# PIC32CX5112MTSH128S1 register map
Vendor: Microchip Technology; Series: PIC32CXMTSH; File version: 0
CPU: CM4 r0p1, selectable endian, MPU, FPU, 4 interrupt priority bits
Registers are 32-bit, read-write, reset 0x0 unless marked. A register's access mark holds for its fields unless they carry their own. Offsets are from the block's base; [hi:lo] are bit positions; lines under a group give offsets from that group; {n}, {i} and the like mark numbered series; 'fields as' and 'values as' point back to an identical list.

## TC0 — Timer Counter
Base 0x40038000; register names take the prefix TC_
Same registers: TC1 0x4003C000, TC2 0x40040000, TC3 0x48008000
{0x0+0x40*i} TC_CHANNEL[{i}] (i=0..2) group
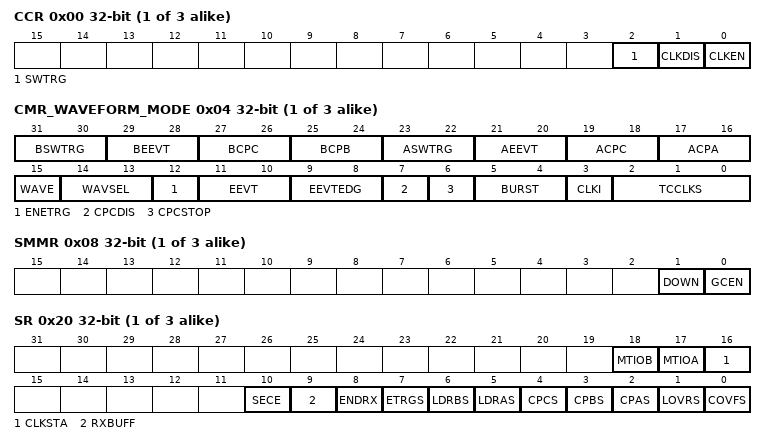
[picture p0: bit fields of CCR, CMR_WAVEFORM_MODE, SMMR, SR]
  0x00 CCR wo — Channel Control Register
    [2] SWTRG — Software Trigger Command
    [1] CLKDIS — Counter Clock Disable Command
    [0] CLKEN — Counter Clock Enable Command
  0x04 CMR_CAPTURE_MODE — Channel Mode Register
    [22:20] SBSMPLR — Loading Edge Subsampling Ratio
      0=ONE (Load a Capture register each selected edge); 1=HALF (Load a Capture register every 2 selected edges); 2=FOURTH (Load a Capture register every 4 selected edges); 3=EIGHTH (Load a Capture register every 8 selected edges); 4=SIXTEENTH (Load a Capture register every 16 selected edges)
    [19:18] LDRB — RB Loading Edge Selection
      0=NONE; 1=RISING (Rising edge of TIOAx); 2=FALLING (Falling edge of TIOAx); 3=EDGE (Each edge of TIOAx)
    [17:16] LDRA — RA Loading Edge Selection
      values as LDRB
    [15] WAVE — Waveform Mode
    [15] WAVE — Waveform Mode
    [14] CPCTRG — RC Compare Trigger Enable
    [10] ABETRG — TIOAx or TIOBx External Trigger Selection
    [9:8] ETRGEDG — External Trigger Edge Selection
      0=NONE (The clock is not gated by an external signal.); 1=RISING (Rising edge); 2=FALLING (Falling edge); 3=EDGE (Each edge)
    [7] LDBDIS — Counter Clock Disable with RB Loading
    [6] LDBSTOP — Counter Clock Stopped with RB Loading
    [5:4] BURST — Burst Signal Selection
      0=NONE (The clock is not gated by an external signal.); 1=XC0 (XC0 is ANDed with the selected clock.); 2=XC1 (XC1 is ANDed with the selected clock.); 3=XC2 (XC2 is ANDed with the selected clock.)
    [3] CLKI — Clock Invert
    [2:0] TCCLKS — Clock Selection
      0=TIMER_CLOCK1 (Clock selected: internal GCLK [TC_ID] clock signal (from PMC)); 1=TIMER_CLOCK2 (Clock selected: internal MCK/8 clock signal (from PMC)); 2=TIMER_CLOCK3 (Clock selected: internal MCK/32 clock signal (from PMC)); 3=TIMER_CLOCK4 (Clock selected: internal MCK/128 clock signal (from PMC)); 4=TIMER_CLOCK5 (Clock selected: internal MD_SLCK clock signal (from PMC)); 5=XC0 (Clock selected: XC0); 6=XC1 (Clock selected: XC1); 7=XC2 (Clock selected: XC2)
  0x04 CMR_WAVEFORM_MODE (alternate view of CMR_CAPTURE_MODE) — Channel Mode Register
    [31:30] BSWTRG — Software Trigger Effect on TIOBx
      0=NONE; 1=SET; 2=CLEAR; 3=TOGGLE
    [29:28] BEEVT — External Event Effect on TIOBx
      0=NONE; 1=SET; 2=CLEAR; 3=TOGGLE
    [27:26] BCPC — RC Compare Effect on TIOBx
      0=NONE; 1=SET; 2=CLEAR; 3=TOGGLE
    [25:24] BCPB — RB Compare Effect on TIOBx
      0=NONE; 1=SET; 2=CLEAR; 3=TOGGLE
    [23:22] ASWTRG — Software Trigger Effect on TIOAx
      0=NONE; 1=SET; 2=CLEAR; 3=TOGGLE
    [21:20] AEEVT — External Event Effect on TIOAx
      0=NONE; 1=SET; 2=CLEAR; 3=TOGGLE
    [19:18] ACPC — RC Compare Effect on TIOAx
      0=NONE; 1=SET; 2=CLEAR; 3=TOGGLE
    [17:16] ACPA — RA Compare Effect on TIOAx
      0=NONE; 1=SET; 2=CLEAR; 3=TOGGLE
    [15] WAVE — Waveform Mode
    [14:13] WAVSEL — Waveform Selection
      0=UP (UP mode without automatic trigger on RC Compare); 1=UPDOWN (UPDOWN mode without automatic trigger on RC Compare); 2=UP_RC (UP mode with automatic trigger on RC Compare); 3=UPDOWN_RC (UPDOWN mode with automatic trigger on RC Compare)
    [12] ENETRG — External Event Trigger Enable
    [11:10] EEVT — External Event Selection
      0=TIOB; 1=XC0; 2=XC1; 3=XC2
    [9:8] EEVTEDG — External Event Edge Selection
      0=NONE; 1=RISING (Rising edge); 2=FALLING (Falling edge); 3=EDGE (Each edge)
    [7] CPCDIS — Counter Clock Disable with RC Compare
    [6] CPCSTOP — Counter Clock Stopped with RC Compare
    [5:4] BURST — Burst Signal Selection
      values as TC_CHANNEL[0].CMR_CAPTURE_MODE.BURST
    [3] CLKI — Clock Invert
    [2:0] TCCLKS — Clock Selection
      values as TC_CHANNEL[0].CMR_CAPTURE_MODE.TCCLKS
  0x08 SMMR — Stepper Motor Mode Register
    [1] DOWN — Down Count
    [0] GCEN — Gray Count Enable
  0x10 CV ro — Counter Value
  0x14 RA — Register A
  0x18 RB — Register B
  0x1C RC — Register C
  0x20 SR ro — Interrupt Status Register
    [18] MTIOB — TIOBx Mirror
    [17] MTIOA — TIOAx Mirror
    [16] CLKSTA — Clock Enabling Status
    [10] SECE — Security and/or Safety Event (cleared on read)
    [9] RXBUFF — Reception Buffer Full (cleared by writing TC_RCR or TC_RNCR)
    [8] ENDRX — End of Receiver Transfer (cleared by writing TC_RCR or TC_RNCR)
    [7] ETRGS — External Trigger Status (cleared on read)
    [6] LDRBS — RB Loading Status (cleared on read)
    [5] LDRAS — RA Loading Status (cleared on read)
    [4] CPCS — RC Compare Status (cleared on read)
    [3] CPBS — RB Compare Status (cleared on read)
    [2] CPAS — RA Compare Status (cleared on read)
    [1] LOVRS — Load Overrun Status (cleared on read)
    [0] COVFS — Counter Overflow Status (cleared on read)
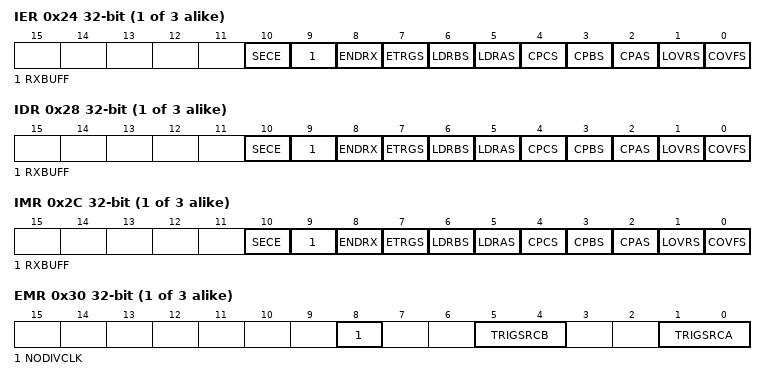
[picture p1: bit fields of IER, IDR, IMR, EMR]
  0x24 IER wo — Interrupt Enable Register
    [10] SECE — Security and/or Safety Event Interrupt Enable
    [9] RXBUFF — Reception Buffer Full
    [8] ENDRX — End of Receiver Transfer
    [7] ETRGS — External Trigger
    [6] LDRBS — RB Loading
    [5] LDRAS — RA Loading
    [4] CPCS — RC Compare
    [3] CPBS — RB Compare
    [2] CPAS — RA Compare
    [1] LOVRS — Load Overrun
    [0] COVFS — Counter Overflow
  0x28 IDR wo — Interrupt Disable Register
    [10] SECE — Security and/or Safety Event Interrupt Disable
    [9] RXBUFF — Reception Buffer Full
    [8] ENDRX — End of Receiver Transfer
    [7] ETRGS — External Trigger
    [6] LDRBS — RB Loading
    [5] LDRAS — RA Loading
    [4] CPCS — RC Compare
    [3] CPBS — RB Compare
    [2] CPAS — RA Compare
    [1] LOVRS — Load Overrun
    [0] COVFS — Counter Overflow
  0x2C IMR ro — Interrupt Mask Register
    [10] SECE — Security and/or Safety Event Interrupt Mask
    [9] RXBUFF — Reception Buffer Full
    [8] ENDRX — End of Receiver Transfer
    [7] ETRGS — External Trigger
    [6] LDRBS — RB Loading
    [5] LDRAS — RA Loading
    [4] CPCS — RC Compare
    [3] CPBS — RB Compare
    [2] CPAS — RA Compare
    [1] LOVRS — Load Overrun
    [0] COVFS — Counter Overflow
  0x30 EMR — Extended Mode Register
    [8] NODIVCLK — No Divided Clock
    [5:4] TRIGSRCB — Trigger Source for Input B
      0=EXTERNAL_TIOBx (The trigger/capture input B is driven by external pin TIOBx); 1=PWMx (The trigger/capture input B is driven internally by the comparator output (see Figure 7-16) of the PWMx.)
    [1:0] TRIGSRCA — Trigger Source for Input A
      0=EXTERNAL_TIOAx (The trigger/capture input A is driven by external pin TIOAx); 1=PWMx (The trigger/capture input A is driven internally by PWMx)
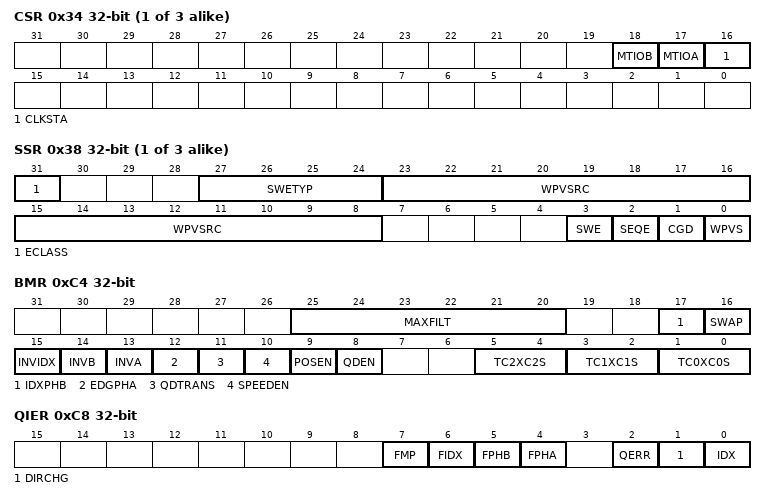
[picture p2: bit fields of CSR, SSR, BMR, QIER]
  0x34 CSR ro — Channel Status Register
    [18] MTIOB — TIOBx Mirror
    [17] MTIOA — TIOAx Mirror
    [16] CLKSTA — Clock Enabling Status
  0x38 SSR ro — Safety Status Register
    [31] ECLASS — Software Error Class
      0=WARNING (An abnormal access that does not have any impact.); 1=ERROR (An abnormal access that may have an impact.)
    [27:24] SWETYP — Software Error Type (cleared on read)
      0=READ_WO (TC Channel x is enabled and a write-only register has been read (Warning).); 1=WRITE_RO (TC Channel x is enabled and a write access has been performed on a read-only register (Warning).); 2=UNDEF_RW (Access to an undefined address of the TC (Warning).); 3=W_RARB_CAPT (TC_RAx or TC_RBx are written while channel is enabled and configured in capture mode (Error).)
    [23:8] WPVSRC — Write Protection Violation Source (cleared on read)
    [3] SWE — Software Control Error (cleared on read)
    [2] SEQE — Internal Sequencer Error (cleared on read)
    [1] CGD — Clock Glitch Detected (cleared on read)
    [0] WPVS — Write Protection Violation Status (cleared on read)
0xC0 BCR wo — Block Control Register
  [0] SYNC — Synchro Command
0xC4 BMR — Block Mode Register
  [25:20] MAXFILT — Maximum Filter
  [17] IDXPHB — Index Pin is PHB Pin
  [16] SWAP — Swap PHA and PHB
  [15] INVIDX — Inverted Index
  [14] INVB — Inverted PHB
  [13] INVA — Inverted PHA
  [12] EDGPHA — Edge on PHA Count Mode
  [11] QDTRANS — Quadrature Decoding Transparent
  [10] SPEEDEN — Speed Enabled
  [9] POSEN — Position Enabled
  [8] QDEN — Quadrature Decoder Enabled
  [5:4] TC2XC2S — External Clock Signal 2 Selection
    0=TCLK2 (Signal connected to XC2: TCLK2); 2=TIOA0 (Signal connected to XC2: TIOA0); 3=TIOA1 (Signal connected to XC2: TIOA1)
  [3:2] TC1XC1S — External Clock Signal 1 Selection
    0=TCLK1 (Signal connected to XC1: TCLK1); 2=TIOA0 (Signal connected to XC1: TIOA0); 3=TIOA2 (Signal connected to XC1: TIOA2)
  [1:0] TC0XC0S — External Clock Signal 0 Selection
    0=TCLK0 (Signal connected to XC0: TCLK0); 2=TIOA1 (Signal connected to XC0: TIOA1); 3=TIOA2 (Signal connected to XC0: TIOA2)
0xC8 QIER wo — QDEC Interrupt Enable Register
  [7] FMP — Filtered Missing Pulse
  [6] FIDX — Filtered Index Line
  [5] FPHB — Filtered Phase B Line
  [4] FPHA — Filtered Phase A Line
  [2] QERR — Quadrature Error
  [1] DIRCHG — Direction Change
  [0] IDX — Index
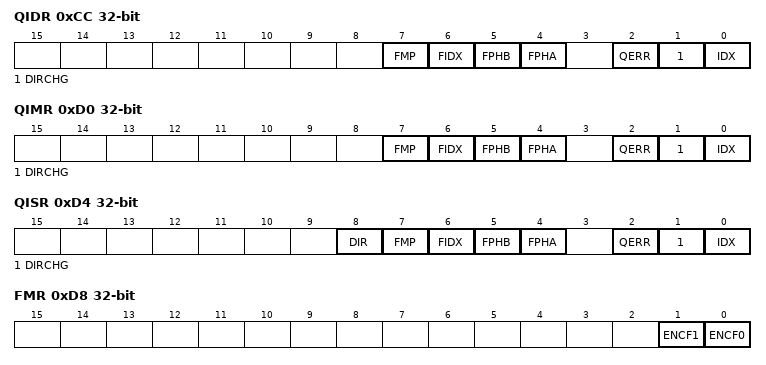
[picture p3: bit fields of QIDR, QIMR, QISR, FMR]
0xCC QIDR wo — QDEC Interrupt Disable Register
  fields as QIER
0xD0 QIMR ro — QDEC Interrupt Mask Register
  fields as QIER
0xD4 QISR ro — QDEC Interrupt Status Register
  [8] DIR — Direction
  [7] FMP — Filtered Missing Pulse
  [6] FIDX — Filtered Index Line
  [5] FPHB — Filtered Phase B Line
  [4] FPHA — Filtered Phase A Line
  [2] QERR — Quadrature Error
  [1] DIRCHG — Direction Change
  [0] IDX — Index
0xD8 FMR — Fault Mode Register
  [1] ENCF1 — Enable Compare Fault Channel 1
  [0] ENCF0 — Enable Compare Fault Channel 0
0xDC QSR ro — QDEC Status Register
  [8] DIR — Direction
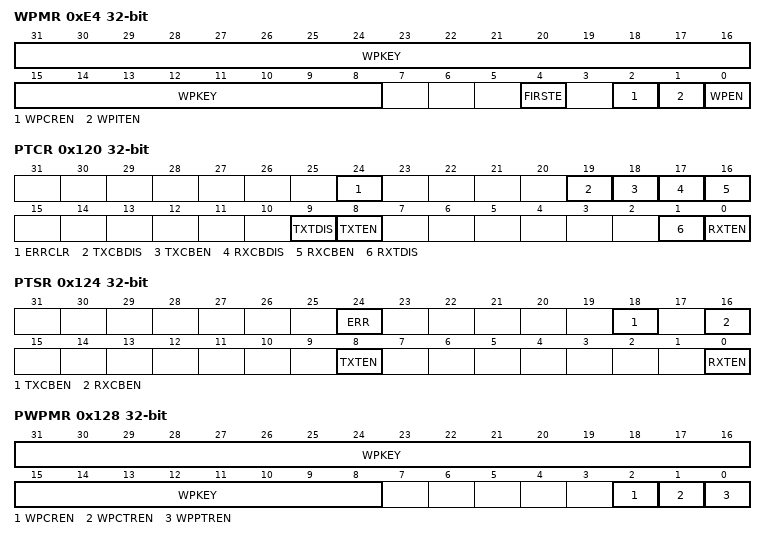
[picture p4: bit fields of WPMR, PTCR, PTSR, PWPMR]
0xE4 WPMR — Write Protection Mode Register
  [31:8] WPKEY — Write Protection Key
    0x54494D=PASSWD (Writing any other value in this field aborts the write operation of the WPEN bit. Always reads as 0.)
  [4] FIRSTE — First Error Report Enable
  [2] WPCREN — Write Protection Control Enable
  [1] WPITEN — Write Protection Interrupt Enable
  [0] WPEN — Write Protection Enable
0x100 RPR — Receive Pointer Register
  [31:0] RXPTR
0x104 RCR — Receive Counter Register
  [15:0] RXCTR
0x110 RNPR — Receive Next Pointer Register
  [31:0] RXNPTR — Receive Next Pointer
0x114 RNCR — Receive Next Counter Register
  [15:0] RXNCTR — Receive Next Counter
0x120 PTCR wo — Transfer Control Register
  [24] ERRCLR — Transfer Bus Error Clear
  [19] TXCBDIS — Transmitter Circular Buffer Disable
  [18] TXCBEN — Transmitter Circular Buffer Enable
  [17] RXCBDIS — Receiver Circular Buffer Disable
  [16] RXCBEN — Receiver Circular Buffer Enable
  [9] TXTDIS — Transmitter Transfer Disable
  [8] TXTEN — Transmitter Transfer Enable
  [1] RXTDIS — Receiver Transfer Disable
  [0] RXTEN — Receiver Transfer Enable
0x124 PTSR ro — Transfer Status Register
  [24] ERR — Transfer Bus Error
  [18] TXCBEN — Transmitter Circular Buffer Enable
  [16] RXCBEN — Receiver Circular Buffer Enable
  [8] TXTEN — Transmitter Transfer Enable
  [0] RXTEN — Receiver Transfer Enable
0x128 PWPMR — Write Protection Mode Register
  [31:8] WPKEY — Write Protection Key
    0x504443=PASSWD (Writing any other value in this field aborts the write operation. Always reads as 0.)
  [2] WPCREN — Write Protection Control Register Enable
  [1] WPCTREN — Write Protection Counter Registers Enable
  [0] WPPTREN — Write Protection Pointer Registers Enable
